# NANO100BN_v1 register map
File version: 1.0
Registers are 32-bit, read-write, reset 0x0 unless marked. A register's access mark holds for its fields unless they carry their own. Offsets are from the block's base; [hi:lo] are bit positions.

## GCR — GCR Register Map
Base 0x50000000
0x00 PDID ro reset 0x140018 — Part Device Identification number Register
  [31:0] PDID — Part Device ID. This register reflects device part number code. Software can read this register to identify which device is used.
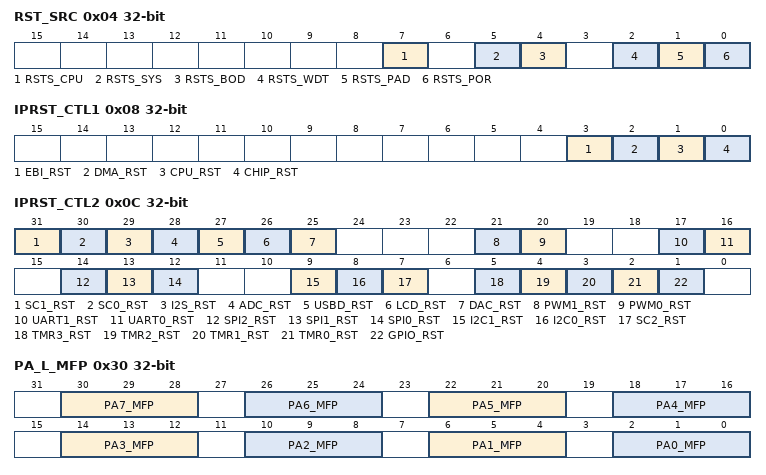
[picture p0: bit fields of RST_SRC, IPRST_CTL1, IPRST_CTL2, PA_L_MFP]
0x04 RST_SRC (reset mask 0xFFFFFF00) — System Reset Source Register
  [7] RSTS_CPU — The RSTS_CPU flag is set by hardware if software writes CPU_RST (IPRST_CTL1[1]) "1" to rest Cortex-M0 CPU kernel and Flash memory controller (FMC). This bit is cleared by writing 1 to itself.
    0=No reset from CPU; 1=Cortex-M0 CPU kernel and FMC are reset by software setting CPU_RST to 1
  [5] RSTS_SYS — The RSTS_SYS flag is set by the "reset signal" from the Cortex_M0 kernel to indicate the previous reset source. This bit is cleared by writing 1 to itself.
    0=No reset from Cortex_M0; 1=Cortex_M0 had issued the reset signal to reset the system by writing 1 to the bit SYSRESTREQ(AIRCR[2], Application Interrupt and Reset Control Register) in system control registers of Cortex_M0 kernel
  [4] RSTS_BOD — The RSTS_BOD flag is set by the "reset signal" from the Brown-out-Detected module to indicate the previous reset source. This bit is cleared by writing 1 to itself.
    0=No reset from BOD; 1=Brown-out-Detected module had issued the reset signal to reset the system
  [2] RSTS_WDT — The RSTS_WDT flag is set by the "reset signal" from the Watchdog Timer module to indicate the previous reset source. This bit is cleared by writing 1 to itself.
    0=No reset from Watchdog Timer; 1=The Watchdog Timer module had issued the reset signal to reset the system
  [1] RSTS_PAD — The RSTS_PAD flag is set by the "reset signal" from the /RESET pin to indicate the previous reset source. This bit is cleared by writing 1 to itself.
    0=No reset from /RESET pin; 1=The /RESET pin had issued the reset signal to reset the system
  [0] RSTS_POR — The RSTS_POR flag is set by the "reset signal" from the Power-on Reset (POR) module or bit CHIP_RST (IPRSTC1[0]) to indicate the previous reset source. This bit is cleared by writing 1 to itself.
    0=No reset from POR or CHIP_RST; 1=Power-on Reset (POR) or CHIP_RST had issued the reset signal to reset the system
0x08 IPRST_CTL1 — IP Reset Control Resister1
  [3] EBI_RST — EBI Controller Reset. This is a protected register. Please refer to open lock sequence to program it. Set this bit "1" will generate a reset signal to the EBI. SW needs to set this bit to low to release reset signal.
    0=Normal operation; 1=EBI IP reset
  [2] DMA_RST — DMA Controller Reset. This is a protected register. Please refer to open lock sequence to program it. Set this bit "1" will generate a reset signal to the DMA. SW needs to set this bit to low to release reset signal.
    0=Normal operation; 1=DMA IP reset
  [1] CPU_RST — CPU kernel one shot reset. This is a protected register. Please refer to open lock sequence to program it. Setting this bit will only reset the CPU kernel and Flash Memory Controller(FMC), and this bit will automatically return to "0" after the 2 clock cycles
    0=Normal; 1=Reset CPU
  [0] CHIP_RST — CHIP one shot reset. This is a protected register. Please refer to open lock sequence to program it. Setting this bit will reset the whole chip, including CPU kernel and all peripherals like power-on reset and this bit will automatically return to "0" after the 2 clock cycles. The chip setting from flash will be also reloaded when chip one shot reset. Note: In the following conditions, chip setting from flash will be reloaded. Power-on Reset. Brown-out-Detected Reset. Low level on the /RESET pin. Set IPRST_CTL1[CHIP_RST]
    0=Normal; 1=Reset CHIP
0x0C IPRST_CTL2 — IP Reset Control Resister2
  [31] SC1_RST — SmartCard1 Controller Reset
    0=SmartCard block normal operation; 1=SmartCard block reset
  [30] SC0_RST — SmartCard 0 Controller Reset
    0=SmartCard block normal operation; 1=SmartCard block reset
  [29] I2S_RST — I2S Controller Reset
    0=I2S block normal operation; 1=I2S block reset
  [28] ADC_RST — ADC Controller Reset
    0=ADC block normal operation; 1=ADC block reset
  [27] USBD_RST — USB Device Controller Reset
    0=USB block normal operation; 1=USB block reset
  [26] LCD_RST — LCD Controller Reset
    0=LCD block normal operation; 1=LCD block reset
  [25] DAC_RST — DAC Controller Reset
    0=DAC block normal operation; 1=DAC block reset
  [21] PWM1_RST — PWM1 controller Reset
    0=PWM1 block normal operation; 1=PWM1 block reset
  [20] PWM0_RST — PWM0 controller Reset
    0=PWM0 block normal operation; 1=PWM0 block reset
  [17] UART1_RST — UART1 controller Reset
    0=UART1 normal operation; 1=UART1 block reset
  [16] UART0_RST — UART0 controller Reset
    0=UART0 normal operation; 1=UART0 block reset
  [14] SPI2_RST — SPI2 controller Reset
    0=SPI2 normal operation; 1=SPI2 block reset
  [13] SPI1_RST — SPI1 controller Reset
    0=SPI1 normal operation; 1=SPI1 block reset
  [12] SPI0_RST — SPI0 controller Reset
    0=SPI0 block normal operation; 1=SPI0 block reset
  [9] I2C1_RST — I2C1 controller Reset
    0=I2C1 block normal operation; 1=I2C1 block reset
  [8] I2C0_RST — I2C0 controller Reset
    0=I2C0 normal operation; 1=I2C0 block reset
  [7] SC2_RST — SmartCard 2 Controller Reset
    0=SmartCard 2 block normal operation; 1=SmartCard 2 block reset
  [5] TMR3_RST — Timer3 controller Reset
    0=Timer3 normal operation; 1=Timer3 block reset
  [4] TMR2_RST — Timer2 controller Reset
    0=Timer2 normal operation; 1=Timer2 block reset
  [3] TMR1_RST — Timer1 controller Reset
    0=Timer1 normal operation; 1=Timer1 block reset
  [2] TMR0_RST — Timer0 controller Reset
    0=Timer0 normal operation; 1=Timer0 reset
  [1] GPIO_RST — GPIO controller Reset
    0=GPIO normal operation; 1=GPIO reset
0x20 TEMPCTL — Temperature Sensor Control Register
  [0] VTEMP_EN — Temperature Sensor Enable
    0=Temperature sensor function Disabled (default); 1=Temperature sensor function Enabled
0x30 PA_L_MFP — Port A low byte multiple function control register
  [30:28] PA7_MFP — PA.7 Pin Function Selection
  [26:24] PA6_MFP — PA.6 Pin Function Selection
  [22:20] PA5_MFP — PA.5 Pin Function Selection
  [18:16] PA4_MFP — PA.4 Pin Function Selection
  [14:12] PA3_MFP — PA.3 Pin Function Selection
  [10:8] PA2_MFP — PA.2 Pin Function Selection
  [6:4] PA1_MFP — PA.1 Pin Function Selection
  [2:0] PA0_MFP — PA.0 Pin Function Selection
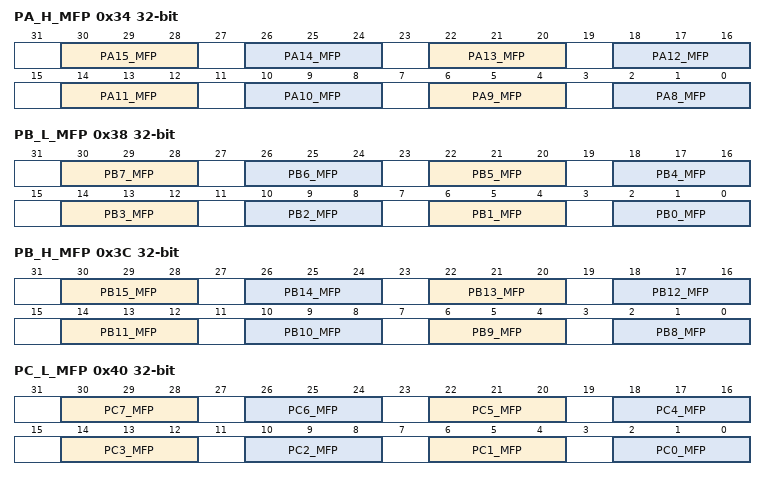
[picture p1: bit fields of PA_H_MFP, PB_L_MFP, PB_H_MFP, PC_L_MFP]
0x34 PA_H_MFP — Port A high byte multiple function control register
  [30:28] PA15_MFP — PA.15 Pin Function Selection
  [26:24] PA14_MFP — PA.14 Pin Function Selection
  [22:20] PA13_MFP — PA.13 Pin Function Selection
  [18:16] PA12_MFP — PA.12 Pin Function Selection
  [14:12] PA11_MFP — PA.11 Pin Function Selection
  [10:8] PA10_MFP — PA.10 Pin Function Selection
  [6:4] PA9_MFP — PA.9 Pin Function Selection
  [2:0] PA8_MFP — PA.8 Pin Function Selection
0x38 PB_L_MFP — Port B low byte multiple function control register
  [30:28] PB7_MFP — PB.7 Pin Function Selection
  [26:24] PB6_MFP — PB.6 Pin Function Selection
  [22:20] PB5_MFP — PB.5 Pin Function Selection
  [18:16] PB4_MFP — PB.4 Pin Function Selection
  [14:12] PB3_MFP — PB.3 Pin Function Selection
  [10:8] PB2_MFP — PB.2 Pin Function Selection
  [6:4] PB1_MFP — PB.1 Pin Function Selection
  [2:0] PB0_MFP — PB.0 Pin Function Selection
0x3C PB_H_MFP — Port B high byte multiple function control register
  [30:28] PB15_MFP — PB.15 Pin Function Selection
  [26:24] PB14_MFP — PB.14 Pin Function Selection
  [22:20] PB13_MFP — PB.13 Pin Function Selection
  [18:16] PB12_MFP — PB.12 Pin Function Selection
  [14:12] PB11_MFP — PB.11 Pin Function Selection
  [10:8] PB10_MFP — PB.10 Pin Function Selection
  [6:4] PB9_MFP — PB.9 Pin Function Selection
  [2:0] PB8_MFP — PB.8 Pin Function Selection
0x40 PC_L_MFP — Port C low byte multiple function control register
  [30:28] PC7_MFP — PC.7 Pin Function Selection
  [26:24] PC6_MFP — PC.6 Pin Function Selection
  [22:20] PC5_MFP — PC.5 Pin Function Selection
  [18:16] PC4_MFP — PC.4 Pin Function Selection
  [14:12] PC3_MFP — PC.3 Pin Function Selection
  [10:8] PC2_MFP — PC.2 Pin Function Selection
  [6:4] PC1_MFP — PC.1 Pin Function Selection
  [2:0] PC0_MFP — PC.0 Pin Function Selection
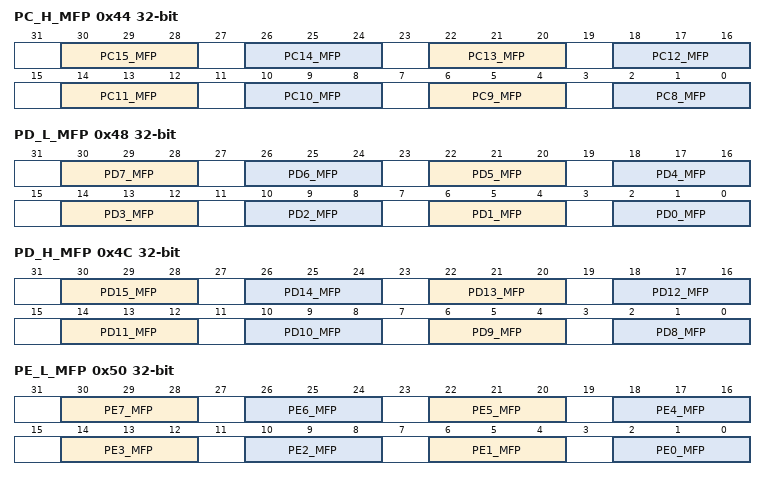
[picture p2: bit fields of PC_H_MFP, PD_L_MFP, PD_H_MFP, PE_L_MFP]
0x44 PC_H_MFP — Port C high byte multiple function control register
  [30:28] PC15_MFP — PC.15 Pin Function Selection
  [26:24] PC14_MFP — PC.14 Pin Function Selection
  [22:20] PC13_MFP — PC.13 Pin Function Selection
  [18:16] PC12_MFP — PC.12 Pin Function Selection
  [14:12] PC11_MFP — PC.11 Pin Function Selection
  [10:8] PC10_MFP — PC.10 Pin Function Selection
  [6:4] PC9_MFP — PC.9 Pin Function Selection
  [2:0] PC8_MFP — PC.8 Pin Function Selection
0x48 PD_L_MFP — Port D low byte multiple function control register
  [30:28] PD7_MFP — PD.7 Pin Function Selection
  [26:24] PD6_MFP — PD.6 Pin Function Selection
  [22:20] PD5_MFP — PD.5 Pin Function Selection
  [18:16] PD4_MFP — PD.4 Pin Function Selection
  [14:12] PD3_MFP — PD.3 Pin Function Selection
  [10:8] PD2_MFP — PD.2 Pin Function Selection
  [6:4] PD1_MFP — PD.1 Pin Function Selection
  [2:0] PD0_MFP — PD.0 Pin Function Selection
0x4C PD_H_MFP — Port D high byte multiple function control register
  [30:28] PD15_MFP — PD.15 Pin Function Selection
  [26:24] PD14_MFP — PD.14 Pin Function Selection
  [22:20] PD13_MFP — PD.13 Pin Function Selection
  [18:16] PD12_MFP — PD.12 Pin Function Selection
  [14:12] PD11_MFP — PD.11 Pin Function Selection
  [10:8] PD10_MFP — PD.10 Pin Function Selection
  [6:4] PD9_MFP — PD.9 Pin Function Selection
  [2:0] PD8_MFP — PD.8 Pin Function Selection
0x50 PE_L_MFP — Port E low byte multiple function control register
  [30:28] PE7_MFP — PE.7 Pin Function Selection
  [26:24] PE6_MFP — PE.6 Pin Function Selection. At LQFP-128 Package: GPIOE[6]. At LQFP-64 Package: GPIOE[6]. At LQFP-48 Package: GPIOE[6]
  [22:20] PE5_MFP — PE.5 Pin Function Selection
  [18:16] PE4_MFP — PE.4 Pin Function Selection
  [14:12] PE3_MFP — PE.3 Pin Function Selection
  [10:8] PE2_MFP — PE.2 Pin Function Selection
  [6:4] PE1_MFP — PE.1 Pin Function Selection
  [2:0] PE0_MFP — PE.0 Pin Function Selection
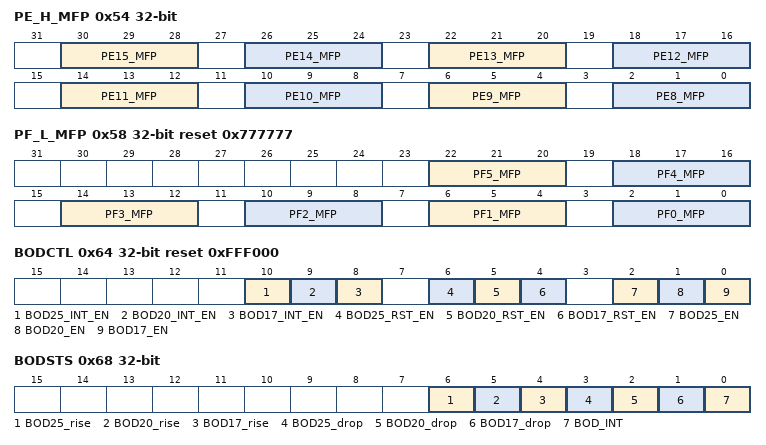
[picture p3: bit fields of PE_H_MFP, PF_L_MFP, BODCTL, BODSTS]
0x54 PE_H_MFP — Port E high byte multiple function control register
  [30:28] PE15_MFP — PE.15 Pin Function Selection
  [26:24] PE14_MFP — PE.14 Pin Function Selection
  [22:20] PE13_MFP — PE.13 Pin Function Selection
  [18:16] PE12_MFP — PE.12 Pin Function Selection
  [14:12] PE11_MFP — PE.11 Pin Function Selection
  [10:8] PE10_MFP — PE.10 Pin Function Selection
  [6:4] PE9_MFP — PE.9 Pin Function Selection
  [2:0] PE8_MFP — PE.8 Pin Function Selection
0x58 PF_L_MFP reset 0x777777 — Port F low byte multiple function control register
  [22:20] PF5_MFP — PF.5 Pin Function Selection
  [18:16] PF4_MFP — PF.4 Pin Function Selection
  [14:12] PF3_MFP — PF.3 Pin Function Selection
  [10:8] PF2_MFP — PF.2 Pin Function Selection
  [6:4] PF1_MFP — PF.1 Pin Function Selection
  [2:0] PF0_MFP — PF.0 Pin Function Selection
0x60 PORCTL — Power-On-Reset Controller Register
  [15:0] POR_DIS_CODE — Power-on Reset Enable Control. This is a protected register. Please refer to open lock sequence to program it. When powered on, the POR circuit generates a reset signal to reset the whole chip function, but noise on the power may cause the POR active again. If setting the POR_DIS_CODE to 0x5AA5, the POR reset function will be disabled and the POR function will be active again when POR_DIS_CODE is set to another value or POR_DIS_CODE is reset by chip other reset functions, including: /RESET, Watchdog Timer reset, BOD reset, ICE reset command and the software-chip reset function
0x64 BODCTL reset 0xFFF000 (reset mask 0xFFFFFF00) — Brown-out Detector Controller Register
  [10] BOD25_INT_EN — BOD 2.5 V interrupt Enable. This is a protected register. Please refer to open lock sequence to program it.
    0=Interrupt does not issue when BOD25 occurs; 1=Interrupt issues when BOD25 occurs
  [9] BOD20_INT_EN — BOD 2.0 V interrupt Enable. This is a protected register. Please refer to open lock sequence to program it.
    0=Interrupt does not issue when BOD20 occurs; 1=Interrupt issues when BOD20 occurs
  [8] BOD17_INT_EN — BOD 1.7 V interrupt Enable. This is a protected register. Please refer to open lock sequence to program it.
    0=Interrupt does not issue when BOD17 occurs; 1=Interrupt issues when BOD17 occurs
  [6] BOD25_RST_EN — BOD 2.5 V Reset Enable. This is a protected register. Please refer to open lock sequence to program it. The default value is set by flash controller user configuration register config0 bit[20:19]
    0=Reset does not issue when BOD25 occurs; 1=Reset issues when BOD25 occurs
  [5] BOD20_RST_EN — BOD 2.0 V Reset Enable. This is a protected register. Please refer to open lock sequence to program it. The default value is set by flash controller user configuration register config0 bit[20:19]
    0=Reset does not issue when BOD20 occurs; 1=Reset issues when BOD20 occurs
  [4] BOD17_RST_EN — BOD 1.7 V Reset Enable
    0=Reset does not issue when BOD17 occurs; 1=Reset issues when BOD17 occurs
  [2] BOD25_EN — Brown-out Detector 2.5 V Function Enable. This is a protected register. Please refer to open lock sequence to program it.
    0=Brown-out Detector 2.5 V function Disabled; 1=Brown-out Detector 2.5 V function Enabled
  [1] BOD20_EN — Brown-out Detector 2.0 V Function Enable. This is a protected register. Please refer to open lock sequence to program it. BOD20_EN is default on. If SW disables it, Brown-out Detector 2.0 V function is not disabled until chip enters power-down mode. If system is not in power-down mode, BOD20_EN will be enabled by hardware automatically.
    0=Brown-out Detector 2.0 V function Disabled; 1=Brown-out Detector 2.0 V function Enabled
  [0] BOD17_EN — Brown-out Detector 1.7V Function Enable
    0=Brown-out Detector 1.7V function Disabled; 1=Brown-out Detector 1.7V function Enabled
0x68 BODSTS ro — Brown-out Detector Status Register
  [6] BOD25_rise — Brown-out Detector higher than 2.5V Status. Setting BOD25_rise high means once the detected voltage is higher than target detected voltage setting (2.5V). Software can write 1 to clear BOD25_rise.
  [5] BOD20_rise — Brown-out Detector higher than 2.0V Status. Setting BOD20_rise high means once the detected voltage is higher than target detected voltage setting (2.0V). Software can write 1 to clear BOD20_rise
  [4] BOD17_rise — Brown-out Detector higher than 1.7V Status. Setting BOD17_rise high means once the detected voltage is higher than target detected voltage setting (1.7V). Software can write 1 to clear BOD17_rise
  [3] BOD25_drop — Brown-out Detector lower than 2.5V Status. Setting BOD25_drop high means once the detected voltage is lower than target detected voltage setting (2.5V). Software can write 1 to clear BOD25_drop
  [2] BOD20_drop — Brown-out Detector lower than 2.0V Status. Setting BOD20_drop high means once the detected voltage is lower than target detected voltage setting (2.0V). Software can write 1 to clear BOD20_drop
  [1] BOD17_drop — Brown-out Detector lower than 1.7V Status. Setting BOD17_drop high means once the detected voltage is lower than target detected voltage setting (1.7V). Software can write 1 to clear BOD17_drop
  [0] BOD_INT — Brown-out Detector interrupt status. This bit is cleared by writing 1 to itself.
    0=Brown-out Detector does not detect any voltage drift at VDD down through or up through the target detected voltage after interrupt is enabled; 1=When Brown-out Detector detects the VDD is dropped down through the target detected voltage or the VDD is raised up through the target detected voltage and Brown-out interrupt is enabled, this bit will be set to 1
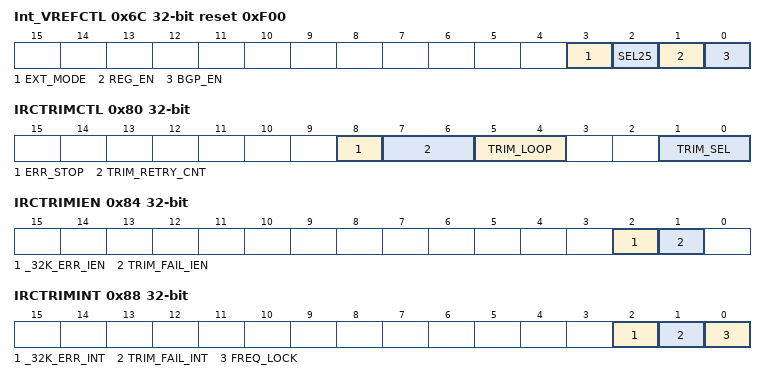
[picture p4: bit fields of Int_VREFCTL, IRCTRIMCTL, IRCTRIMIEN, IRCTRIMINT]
0x6C Int_VREFCTL reset 0xF00 — Voltage reference Control register
  [3] EXT_MODE — Regulator External Mode. This is a protected register. Please refer to open lock sequence to program it. Users can output regulator output voltage in VREF pin if EXT_MODE is high.
    0=No connection with external VREF pin; 1=Connet to external VREF pin. Connect a 1uF to 10uF capacitor to AVSS will let internal voltage reference be more stable
  [2] SEL25 — Regulator Output Voltage Selection. Select internal reference voltage level. This is a protected register. Please refer to open lock sequence to program it.
    0=1.8V; 1=2.5V
  [1] REG_EN — Regulator Enable. Enable internal 1.8V or 2.5V reference voltage. This is a protected register. Please refer to open lock sequence to program it.
    0=Disabled; 1=Enabled
  [0] BGP_EN — Band-gap Enable. This is a protected register. Please refer to open lock sequence to program it. Band-gap is the reference voltage of internal reference voltage. User must enable band-gap if want to enable internal 1.8V or 2.5V reference voltage.
    0=Disabled; 1=Enabled
0x80 IRCTRIMCTL — HIRC Trim Control Register
  [8] ERR_STOP — Trim Stop When 32.768 kHz Error Detected. This bit is used to control if stop the HIRC trim operation when 32.768 kHz clock error is detected. If set this bit high and 32.768 kHz clock error detected, the status 32K_ERR_INT would be set high and HIRC trim operation was stopped. If this bit is low and 32.768 kHz clock error detected, the status 23K_ERR_INT would be set high and HIRC trim operation is continuously.
    0=Continue the HIRC trim operation even if 32.768 kHz clock error detected; 1=Stop the HIRC trim operation if 32.768 kHz clock error detected
  [7:6] TRIM_RETRY_CNT — Trim Value Update Limitation Count
  [5:4] TRIM_LOOP — Trim Calculation Loop
  [1:0] TRIM_SEL — Trim Frequency Selection
0x84 IRCTRIMIEN — HIRC Trim Interrupt Enable Register
  [2] _32K_ERR_IEN — 32.768 kHz Clock Error Interrupt Enable. This bit controls if CPU would get an interrupt while 32.768 kHz clock is inaccuracy during auto trim operation. If this bit is high, and 32K_ERR_INT is set during auto trim operation, an interrupt will be triggered to notify the 32.768 kHz clock frequency is inaccuracy.
    0=32K_ERR_INT status Disabled to trigger an interrupt to CPU; 1=32K_ERR_INT status Enabled to trigger an interrupt to CPU
  [1] TRIM_FAIL_IEN — Trim Failure Interrupt Enable. This bit controls if an interrupt will be triggered while HIRC trim value update limitation count reached and HIRC frequency still not locked on target frequency set by TRIM_SEL. If this bit is high and TRIM_FAIL_INT is set during auto trim operation, an interrupt will be triggered to notify that HIRC trim value update limitation count was reached.
    0=TRIM_FAIL_INT status Disabled to trigger an interrupt to CPU; 1=TRIM_FAIL_INT status Enabled to trigger an interrupt to CPU
0x88 IRCTRIMINT — HIRC Trim Interrupt Status Register
  [2] _32K_ERR_INT — 32.768 kHz Clock Error Interrupt Status. This bit indicates that 32.768 kHz clock frequency is inaccuracy. Once this bit is set, the auto trim operation stopped and TRIM_SEL will be cleared to 00 by hardware automatically. If this bit is set and 32K_ERR_IEN is high, an interrupt will be triggered to notify the 32.768 kHz clock frequency is inaccuracy. Write 1 to clear this to zero.
    0=32.768 kHz clock frequency is accuracy; 1=32.768 kHz clock frequency is inaccuracy
  [1] TRIM_FAIL_INT — Trim Failure Interrupt Status. This bit indicates that HIRC trim value update limitation count reached and HIRC clock frequency still doesn't lock. Once this bit is set, the auto trim operation stopped and TRIM_SEL will be cleared to 00 by hardware automatically. If this bit is set and TRIM_FAIL_IEN is high, an interrupt will be triggered to notify that HIRC trim value update limitation count was reached. Write 1 to clear this to zero.
    0=Trim value update limitation count doesn't reach; 1=Trim value update limitation count reached and HIRC frequency still doesn't lock
  [0] FREQ_LOCK — HIRC Frequency Lock Status. This bit indicates the HIRC frequency lock. This is a status bit and doesn't trigger any interrupt.
0x100 RegLockAddr — Register Lock Key address
  [0] RegUnLock
    0=Protected register are Locked. Any write to the target register is ignored; 1=Protected registers are Unlocked
